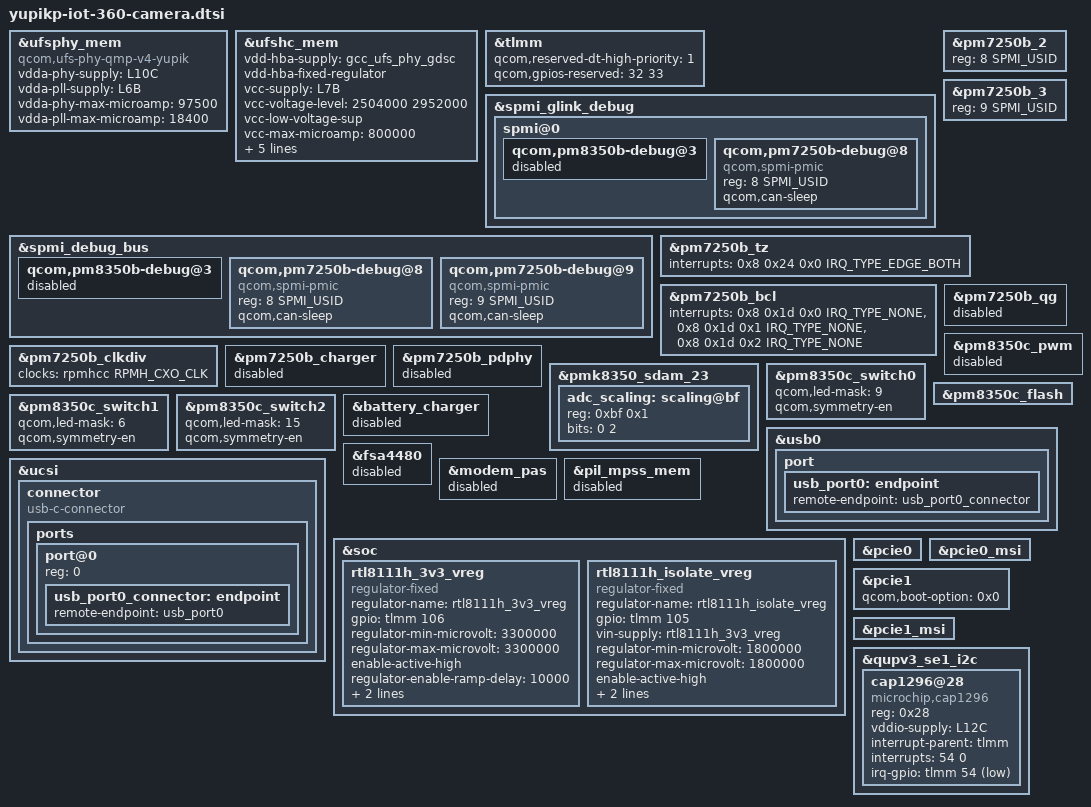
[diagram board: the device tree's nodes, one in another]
// SPDX-License-Identifier: BSD-3-Clause
/*
 * Copyright (c) Qualcomm Technologies, Inc. and/or its subsidiaries.
 */

#include <dt-bindings/gpio/gpio.h>
#include <dt-bindings/clock/qcom,rpmh.h>
#include <dt-bindings/iio/qcom,spmi-vadc.h>
#include <dt-bindings/interconnect/qcom,yupik.h>

#include "yupik-pmic-overlay.dtsi"
#include "pm7250b.dtsi"
#include "yupik-pm7250b-thermal-overlay.dtsi"

/*==============================*/
/*     UFS Related Start        */
/*==============================*/
&ufsphy_mem {
	compatible = "qcom,ufs-phy-qmp-v4-yupik";

	vdda-phy-supply = <&L10C>;
	vdda-pll-supply = <&L6B>;
	vdda-phy-max-microamp = <97500>;
	vdda-pll-max-microamp = <18400>;

	status = "ok";
};

&ufshc_mem {
	vdd-hba-supply = <&gcc_ufs_phy_gdsc>;
	vdd-hba-fixed-regulator;

	vcc-supply = <&L7B>;
	vcc-voltage-level = <2504000 2952000>;
	vcc-low-voltage-sup;
	vcc-max-microamp = <800000>;

	/*
	 * Yupik target supports both UFS2.2 & UFS3.1, here
	 * vccq2 is supplied via eLDO, and that is controlled via
	 * L9B which supports a max voltage of 1.2V, but eLDO would
	 * supply 1.8V. and same L9B acts as vccq voltage for UFS3.1
	 * devices.
	 * Here L9B can max support for 1.2V but UFS GKI driver code
	 * votes for 1.8V, which is leading to failure from pmic
	 * regulator.
	 *
	 * Now since vccq and control of eLDO are common that is L9B
	 * we can use vccq vote as control of eLDO for vccq2.
	 * Hence vccq entries shall be used for both type of UFS
	 * devices only. And vccq entries should not be changed/removed
	 * for any design alteration.
	 */
	vccq-supply = <&L9B>;
	vccq-max-microamp = <900000>;
	vccq-min-microamp = <10000>;

	qcom,vddp-ref-clk-supply = <&L9B>;
	qcom,vddp-ref-clk-max-microamp = <100>;

	status = "ok";

};

/*==============================*/
/*     UFS Related End          */
/*==============================*/
&tlmm {
	qcom,reserved-dt-high-priority = <1>;
	qcom,gpios-reserved = <32 33>;
};

&spmi_glink_debug {
	spmi@0 {
		qcom,pm8350b-debug@3 {
			status = "disabled";
		};

		qcom,pm7250b-debug@8 {
			compatible = "qcom,spmi-pmic";
			reg = <8 SPMI_USID>;
			qcom,can-sleep;
		};
	};

};

&spmi_debug_bus {
	qcom,pm8350b-debug@3 {
		status = "disabled";
	};

	qcom,pm7250b-debug@8 {
		compatible = "qcom,spmi-pmic";
		reg = <8 SPMI_USID>;
		#address-cells = <2>;
		#size-cells = <0>;
		qcom,can-sleep;
	};

	qcom,pm7250b-debug@9 {
		compatible = "qcom,spmi-pmic";
		reg = <9 SPMI_USID>;
		#address-cells = <2>;
		#size-cells = <0>;
		qcom,can-sleep;
	};

};

&pm7250b_2 {
	/* Slave ID - 8 */
	reg = <8 SPMI_USID>;
};

&pm7250b_3 {
	/* Slave ID - 9 */
	reg = <9 SPMI_USID>;
};

&pm7250b_tz {
	interrupts = <0x8 0x24 0x0 IRQ_TYPE_EDGE_BOTH>;
};

&pm7250b_bcl {
	interrupts = <0x8 0x1d 0x0 IRQ_TYPE_NONE>,
			<0x8 0x1d 0x1 IRQ_TYPE_NONE>,
			<0x8 0x1d 0x2 IRQ_TYPE_NONE>;
};

&pm7250b_clkdiv {
	clocks = <&rpmhcc RPMH_CXO_CLK>;
};

&pm7250b_charger {
	status = "disabled";
};

&pm7250b_qg {
	status = "disabled";
};

&pm7250b_pdphy {
	status = "disabled";
};

&pmk8350_sdam_23 {
	adc_scaling: scaling@bf {
		reg = <0xbf 0x1>;
		bits = <0 2>;
	};
};

&spmi_debug_bus {
	status = "ok";
};

&spmi_glink_debug {
	status = "ok";
};

&pm8350c_pwm {
	status = "disabled";
};

&pm8350c_switch0 {
	qcom,led-mask = <9>; /* Channels 1 & 4 */
	qcom,symmetry-en;
};

&pm8350c_switch1 {
	qcom,led-mask = <6>; /* Channels 2 & 3 */
	qcom,symmetry-en;
};

&pm8350c_switch2 {
	qcom,led-mask = <15>; /* All Channels */
	qcom,symmetry-en;
};

&pm8350c_flash {
	status = "ok";
};

&battery_charger {
	status = "disabled";

};

/*==============================*/
/*     USB Related Start        */
/*==============================*/
&usb0 {
	port {
		usb_port0: endpoint {
			remote-endpoint = <&usb_port0_connector>;
		};
	};
};

&ucsi {
	connector {
		compatible = "usb-c-connector";

		ports {
			#address-cells = <1>;
			#size-cells = <0>;

			port@0 {
				reg = <0>;

				usb_port0_connector: endpoint {
					remote-endpoint = <&usb_port0>;
				};
			};
		};
	};
};


&fsa4480 {
	status = "disabled";
};

/*==============================*/
/*     USB Related End          */
/*==============================*/
/*==============================*/
/*     Unwanted Modules Start   */
/*==============================*/

&modem_pas {
	status = "disabled";
};

&pil_mpss_mem {
	status = "disabled";
};

/*==============================*/
/*     Unwanted Modules End     */
/*==============================*/
/*==============================*/
/*     PCIe Related Start       */
/*==============================*/

&soc {
	rtl8111h_3v3_vreg: rtl8111h_3v3_vreg {
		compatible = "regulator-fixed";
		regulator-name = "rtl8111h_3v3_vreg";
		gpio = <&tlmm 106 0>;
		regulator-min-microvolt = <3300000>;
		regulator-max-microvolt = <3300000>;
		enable-active-high;
		regulator-enable-ramp-delay = <10000>;
		regulator-always-on;
		regulator-boot-on;
	};

	rtl8111h_isolate_vreg: rtl8111h_isolate_vreg {
		compatible = "regulator-fixed";
		regulator-name = "rtl8111h_isolate_vreg";
		gpio = <&tlmm 105 0>;
		vin-supply = <&rtl8111h_3v3_vreg>;
		regulator-min-microvolt = <1800000>;
		regulator-max-microvolt = <1800000>;
		enable-active-high;
		regulator-always-on;
		regulator-boot-on;
	};
};

&pcie0 {
	status = "ok";
};

&pcie0_msi {
	status = "ok";
};

&pcie1 {
	status = "ok";
	qcom,boot-option = <0x0>;
};

&pcie1_msi {
	status = "ok";
};

/*==============================*/
/*     PCIe Related End         */
/*==============================*/

&qupv3_se1_i2c {
	status = "ok";

	cap1296@28 {
		compatible = "microchip,cap1296";
		status = "ok";
		reg = <0x28>;
		vddio-supply = <&L12C>;
		interrupt-parent = <&tlmm>;
		interrupts = <54 0>;
		irq-gpio = <&tlmm 54 GPIO_ACTIVE_LOW>;
	};
};


